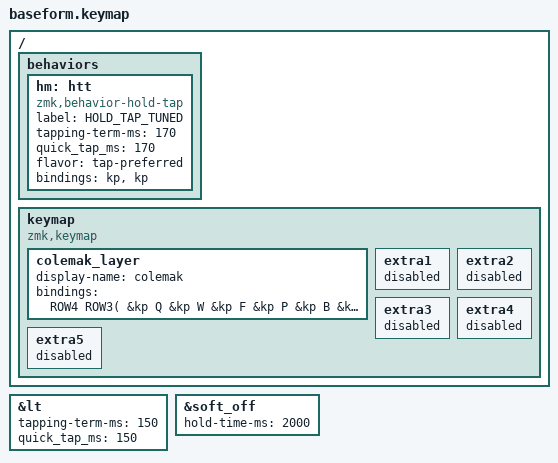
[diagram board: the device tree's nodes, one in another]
#include <behaviors.dtsi>
#include <dt-bindings/zmk/keys.h>
#include <dt-bindings/zmk/bt.h>
#include <dt-bindings/zmk/ext_power.h>
#include <dt-bindings/zmk/outputs.h>
#include "../layer_defs.dtsi"
#include "../keymap_edges.dtsi"

#define COL 0

&lt {
  tapping-term-ms = <150>;
  quick_tap_ms = <150>;
};

&soft_off {
    hold-time-ms = <2000>; 
};

/ {

  behaviors {
    hm: htt {
      compatible = "zmk,behavior-hold-tap";
      label = "HOLD_TAP_TUNED";
      #binding-cells = <2>;
      tapping-term-ms = <170>;
      quick_tap_ms = <170>;
      flavor = "tap-preferred";
      bindings = <&kp>, <&kp>;
    };
  };

  keymap {
    compatible = "zmk,keymap";

    colemak_layer {
      display-name = "colemak";
      bindings = <
        ROW4
        ROW3( &kp Q        &kp W       &kp F  &kp P  &kp B    &kp J  &kp L  &kp U     &kp Y         &kp APOS      )
        ROW2( &kp A        &kp R       &kp S  &kp T  &kp G    &kp M  &kp N  &kp E     &kp I         &kp O         )
        ROW1( &hm LCTRL Z  &hm LALT X  &kp C  &kp D  &kp V    &kp K  &kp H  &kp COMMA &hm RALT DOT  &hm RCTRL RET )
        THUMB_ROW
      >;
    };
 
#include "../shared_layers.dtsi"

    extra1 {
        status = "reserved";
    };

    extra2 {
        status = "reserved";
    };

    extra3 {
        status = "reserved";
    };

    extra4 {
        status = "reserved";
    };

    extra5 {
        status = "reserved";
    };


  };
};
